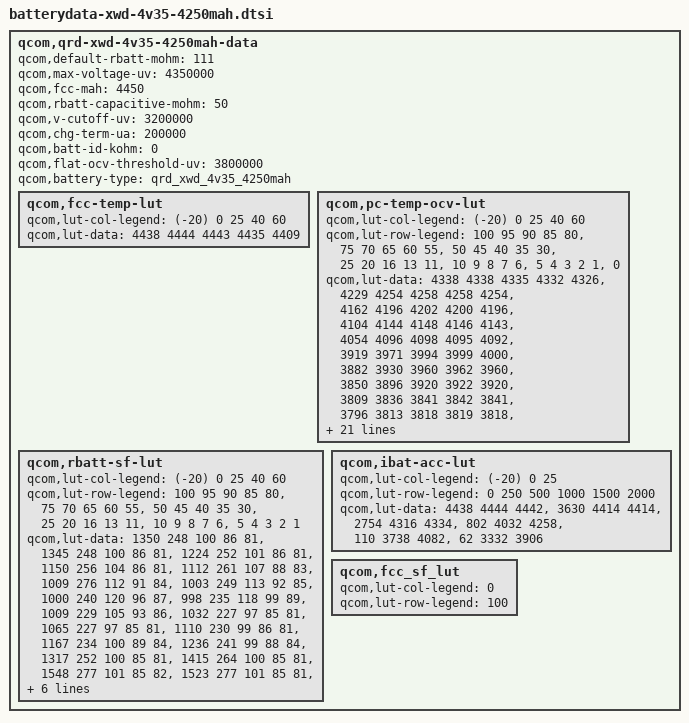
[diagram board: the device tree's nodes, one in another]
/* Copyright (c) 2014, The Linux Foundation. All rights reserved.
 *
 * This program is free software; you can redistribute it and/or modify
 * it under the terms of the GNU General Public License version 2 and
 * only version 2 as published by the Free Software Foundation.
 *
 * This program is distributed in the hope that it will be useful,
 * but WITHOUT ANY WARRANTY; without even the implied warranty of
 * MERCHANTABILITY or FITNESS FOR A PARTICULAR PURPOSE.  See the
 * GNU General Public License for more details.
 */

qcom,qrd-xwd-4v35-4250mah-data {
	qcom,default-rbatt-mohm = <111>;
	qcom,max-voltage-uv = <4350000>;
	qcom,fcc-mah = <4450>;
	qcom,rbatt-capacitive-mohm = <50>;
	qcom,v-cutoff-uv = <3200000>;
	qcom,chg-term-ua = <200000>;
	qcom,batt-id-kohm = <0>;
	qcom,flat-ocv-threshold-uv = <3800000>;
	qcom,battery-type = "qrd_xwd_4v35_4250mah";

	qcom,fcc-temp-lut {
		qcom,lut-col-legend = <(-20) 0 25 40 60>;
		qcom,lut-data = <4438 4444 4443 4435 4409>;
	};

	qcom,pc-temp-ocv-lut {
		qcom,lut-col-legend = <(-20) 0 25 40 60>;
		qcom,lut-row-legend = <100 95 90 85 80>,
				<75 70 65 60 55>,
				<50 45 40 35 30>,
				<25 20 16 13 11>,
				<10 9 8 7 6 >,
				<5 4 3 2 1 >,
				<0>;
		qcom,lut-data = <4338 4338 4335 4332 4326>,
				<4229 4254 4258 4258 4254>,
				<4162 4196 4202 4200 4196>,
				<4104 4144 4148 4146 4143>,
				<4054 4096 4098 4095 4092>,
				<3919 3971 3994 3999 4000>,
				<3882 3930 3960 3962 3960>,
				<3850 3896 3920 3922 3920>,
				<3809 3836 3841 3842 3841>,
				<3796 3813 3818 3819 3818>,
				<3784 3794 3800 3800 3799>,
				<3772 3782 3785 3786 3784>,
				<3760 3772 3772 3769 3764>,
				<3746 3761 3757 3750 3739>,
				<3730 3746 3740 3731 3718>,
				<3714 3728 3721 3712 3699>,
				<3702 3713 3703 3694 3681>,
				<3690 3702 3691 3682 3671>,
				<3683 3698 3688 3680 3670>,
				<3674 3696 3688 3680 3668>,
				<3664 3692 3686 3678 3666>,
				<3652 3688 3682 3675 3664>,
				<3638 3682 3678 3669 3658>,
				<3619 3669 3662 3652 3640>,
				<3592 3637 3625 3615 3602>,
				<3554 3586 3572 3562 3552>,
				<3498 3518 3502 3492 3486>,
				<3451 3468 3452 3441 3432>,
				<3404 3418 3402 3391 3383>,
				<3302 3306 3310 3295 3291>,
				<3200 3200 3219 3200 3200>;
	};

	qcom,rbatt-sf-lut {
		qcom,lut-col-legend = <(-20) 0 25 40 60>;
		qcom,lut-row-legend = <100 95 90 85 80>,
				<75 70 65 60 55>,
				<50 45 40 35 30>,
				<25 20 16 13 11>,
				<10 9 8 7 6>,
				<5 4 3 2 1>;
		qcom,lut-data = <1350 248 100 86 81>,
				<1345 248 100 86 81>,
				<1224 252 101 86 81>,
				<1150 256 104 86 81>,
				<1112 261 107 88 83>,
				<1009 276 112 91 84>,
				<1003 249 113 92 85>,
				<1000 240 120 96 87>,
				<998 235 118 99 89>,
				<1009 229 105 93 86>,
				<1032 227 97 85 81>,
				<1065 227 97 85 81>,
				<1110 230 99 86 81>,
				<1167 234 100 89 84>,
				<1236 241 99 88 84>,
				<1317 252 100 85 81>,
				<1415 264 100 85 81>,
				<1548 277 101 85 82>,
				<1523 277 101 85 81>,
				<1710 287 100 84 80>,
				<1822 296 101 85 81>,
				<1947 307 103 86 83>,
				<2090 321 105 88 84>,
				<2259 337 108 90 87>,
				<2452 356 110 94 89>,
				<2690 377 111 91 86>,
				<2984 391 107 88 83>,
				<3390 420 109 92 85>,
				<3990 470 114 94 86>,
				<5036 537 122 100 93>;
	};

	qcom,ibat-acc-lut {
		qcom,lut-col-legend = <(-20) 0 25>;
		qcom,lut-row-legend = <0 250 500 1000 1500 2000>;
		qcom,lut-data = <4438 4444 4442>,
				<3630 4414 4414>,
				<2754 4316 4334>,
				<802 4032 4258>,
				<110 3738 4082>,
				<62 3332 3906>;
	};
	qcom,fcc_sf_lut {
		qcom,lut-col-legend = <0>;
		qcom,lut-row-legend = <100>;
	};
};
